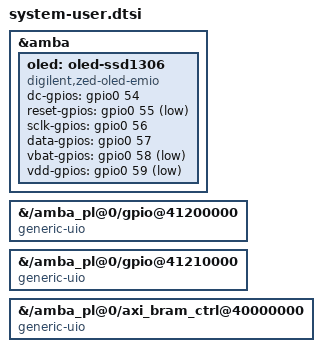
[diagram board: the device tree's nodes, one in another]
#include <dt-bindings/gpio/gpio.h>
#include <dt-bindings/interrupt-controller/irq.h>
/include/ "system-conf.dtsi"

/*
 * system-user.dtsi
 *
 * NOTE: the AXI GPIO / BRAM nodes are auto-generated in pl.dtsi WITHOUT the
 * "axi_gpio_0" style labels (Xilinx DTG 2024.1 names them gpio@<addr>). So we
 * reference them by full PATH, not by &label. Confirm the bus node name and
 * the child node names against the generated pl.dtsi:
 *
 *   grep -nE "amba_pl|gpio@|bram" .../plnx_workspace/device-tree/device-tree/pl.dtsi
 *
 * Adjust /amba_pl@0 and the child @addr names below to match EXACTLY.
 */

&amba {
    /* ---- OLED over EMIO (references PS gpio0, which HAS a stable label) ---- */
    oled: oled-ssd1306 {
        compatible = "digilent,zed-oled-emio";

        dc-gpios    = <&gpio0 54 GPIO_ACTIVE_HIGH>;
        reset-gpios = <&gpio0 55 GPIO_ACTIVE_LOW>;
        sclk-gpios  = <&gpio0 56 GPIO_ACTIVE_HIGH>;
        data-gpios  = <&gpio0 57 GPIO_ACTIVE_HIGH>;
        vbat-gpios  = <&gpio0 58 GPIO_ACTIVE_LOW>;
        vdd-gpios   = <&gpio0 59 GPIO_ACTIVE_LOW>;

        status = "okay";
    };
};

/* Switch/LED GPIO -> UIO  (0x41200000, interrupt from pl.dtsi) */
&{/amba_pl@0/gpio@41200000} {
    compatible = "generic-uio";
    status = "okay";
};

/* Button GPIO -> UIO  (0x41210000, interrupt from pl.dtsi) */
&{/amba_pl@0/gpio@41210000} {
    compatible = "generic-uio";
    status = "okay";
};

/* BRAM controller -> UIO  (0x40000000, no interrupt) */
&{/amba_pl@0/axi_bram_ctrl@40000000} {
    compatible = "generic-uio";
    status = "okay";
};
